# STM32G534xx register map
File version: 1.0
Registers are 32-bit, read-write, reset 0x0 unless marked. A register's access mark holds for its fields unless they carry their own. Offsets are from the block's base; [hi:lo] are bit positions; {n}, {i} and the like mark numbered series; 'fields as' and 'values as' point back to an identical list.

## HRTIM1
Base 0x40010000
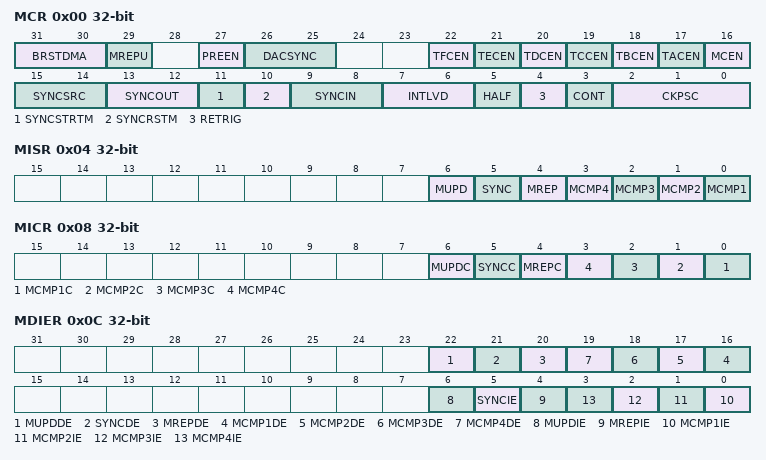
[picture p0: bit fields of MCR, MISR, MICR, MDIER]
0x00 MCR — HRTIM master timer control register
  [31:30] BRSTDMA — Burst DMA update
  [29] MREPU — Master timer repetition update
  [27] PREEN — Preload enable
  [26:25] DACSYNC — DAC synchronization
  [22] TFCEN — Timer F counter enable
  [21] TECEN — Timer E counter enable
  [20] TDCEN — Timer D counter enable
  [19] TCCEN — Timer C counter enable
  [18] TBCEN — Timer B counter enable
  [17] TACEN — Timer A counter enable
  [16] MCEN — Master timer counter enable
  [15:14] SYNCSRC — Synchronization source
  [13:12] SYNCOUT — Synchronization output
  [11] SYNCSTRTM — Synchronization starts master
  [10] SYNCRSTM — Synchronization resets master
  [9:8] SYNCIN — Synchronization input
  [7:6] INTLVD — Interleaved mode
  [5] HALF — Half mode
  [4] RETRIG — Re-triggerable mode
  [3] CONT — Continuous mode
  [2:0] CKPSC — Clock prescaler
0x04 MISR ro — HRTIM master timer interrupt status register
  [6] MUPD — Master update interrupt flag
  [5] SYNC — Sync input interrupt flag
  [4] MREP — Master repetition interrupt flag
  [n-1] MCMP{n} (n=1..4) — Master compare {n} interrupt flag
0x08 MICR — HRTIM master timer interrupt clear register
  [6] MUPDC — Master update interrupt flag clear
  [5] SYNCC — Sync input interrupt flag clear
  [4] MREPC — Repetition interrupt flag clear
  [n-1] MCMP{n}C (n=1..4)
0x0C MDIER — HRTIM master timer DMA interrupt enable register
  [22] MUPDDE — Master update DMA request enable
  [21] SYNCDE — Sync input DMA request enable
  [20] MREPDE
  [n+15] MCMP{n}DE (n=1..4) — Master compare {n} DMA request enable
  [6] MUPDIE — Master update interrupt enable
  [5] SYNCIE — Sync input interrupt enable
  [4] MREPIE — Master repetition interrupt enable
  [n-1] MCMP{n}IE (n=1..4) — Master compare {n} interrupt enable
0x10 MCNTR — HRTIM master timer counter register
  [15:0] MCNT — Counter value
0x14 MPER — HRTIM master timer period register
  [15:0] MPER — Master timer period value
0x18 MREP — HRTIM master timer repetition register
  [7:0] MREP
0x1C MCMP1R — HRTIM master timer compare 1 register
  [15:0] MCMP1 — Master timer compare 1 value
{0x1C+4i} MCMP{i}R (i=2..4) — HRTIM master timer compare {i} register
  [15:0] MCMP{i} — Master timer compare {i} value
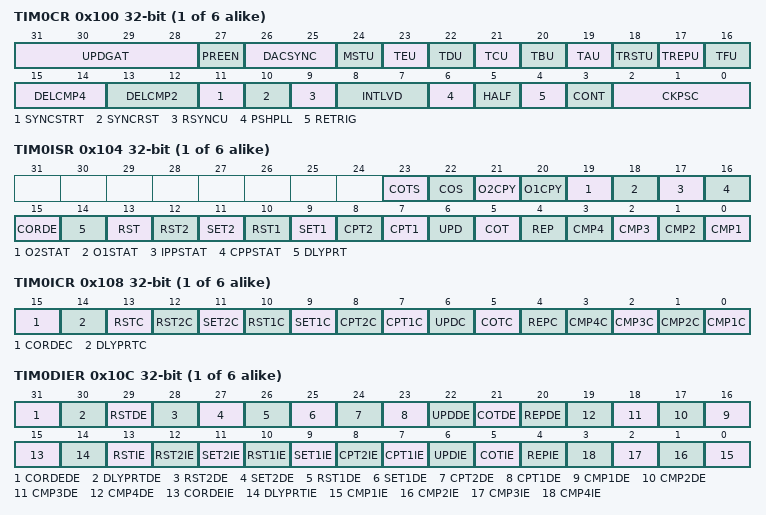
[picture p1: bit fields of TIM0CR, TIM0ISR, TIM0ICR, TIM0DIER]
{0x100+0x100*i} TIM{i}CR (i=0..5) — HRTIM timer x control register
  [31:28] UPDGAT — Update gating
  [27] PREEN — Preload enable
  [26:25] DACSYNC — DAC synchronization
  [24] MSTU — Master timer update
  [23] TEU — Timer E update
  [22] TDU — Timer D update
  [21] TCU — Timer C update
  [20] TBU — Timer B update
  [19] TAU — Timer A update
  [18] TRSTU — Timer x reset update
  [17] TREPU — Timer x repetition update
  [16] TFU — Timer F update
  [15:14] DELCMP4 — CMP4 auto-delayed mode
  [13:12] DELCMP2 — CMP2 auto-delayed mode
  [11] SYNCSTRT — Synchronization starts timer x
  [10] SYNCRST — Synchronization resets timer x
  [9] RSYNCU — Re-synchronized update
  [8:7] INTLVD — Interleaved mode
  [6] PSHPLL — Push-pull mode enable
  [5] HALF — Half mode enable
  [4] RETRIG — Re-triggerable mode
  [3] CONT — Continuous mode
  [2:0] CKPSC — HRTIM timer x clock prescaler
{0x104+0x100*i} TIM{i}ISR ro (i=0..5) — HRTIM timer x interrupt status register
  [23] COTS — Crossbar Override Trigger status
  [22] COS — Crossbar Override status
  [21] O2CPY — Output 2 copy
  [20] O1CPY — Output 1 copy
  [19] O2STAT — Output 2 status
  [18] O1STAT — Output 1 status
  [17] IPPSTAT — Idle push-pull Status
  [16] CPPSTAT — Current push-pull status
  [15] CORDE
  [14] DLYPRT — Delayed protection flag
  [13] RST
  [12] RST2
  [11] SET2
  [10] RST1
  [9] SET1
  [8] CPT2 — Capture 2 interrupt flag
  [7] CPT1 — Capture 1 interrupt flag
  [6] UPD — Update interrupt flag
  [5] COT — Crossbar Override Trigger flag
  [4] REP — Repetition interrupt flag
  [n-1] CMP{n} (n=1..4) — Compare {n} interrupt flag
{0x108+0x100*i} TIM{i}ICR (i=0..5) — HRTIM timer x interrupt clear register
  [15] CORDEC
  [14] DLYPRTC — Delayed protection flag clear
  [13] RSTC — Reset interrupt flag clear
  [12] RST2C — Output 2 reset flag clear timer x
  [11] SET2C — Output 2 set flag clear timer x
  [10] RST1C — Output 1 reset flag clear timer x
  [9] SET1C — Output 1 set flag clear timer x
  [8] CPT2C — Capture 2 interrupt flag clear
  [7] CPT1C — Capture 1 interrupt flag clear
  [6] UPDC — Update interrupt flag clear
  [5] COTC
  [4] REPC — Repetition interrupt flag clear
  [n-1] CMP{n}C (n=1..4) — Compare {n} interrupt flag clear
{0x10C+0x100*i} TIM{i}DIER (i=0..5) — HRTIM timer x DMA interrupt enable register
  [31] CORDEDE
  [30] DLYPRTDE
  [29] RSTDE
  [28] RST2DE
  [27] SET2DE
  [26] RST1DE
  [25] SET1DE
  [24] CPT2DE — Capture 2 DMA request enable
  [23] CPT1DE — Capture 1 DMA request enable
  [22] UPDDE — Update DMA request enable
  [21] COTDE
  [20] REPDE — Repetition DMA request enable
  [n+15] CMP{n}DE (n=1..4) — Compare {n} DMA request enable
  [15] CORDEIE
  [14] DLYPRTIE
  [13] RSTIE — Reset/roll-over interrupt enable
  [12] RST2IE
  [11] SET2IE
  [10] RST1IE
  [9] SET1IE
  [8] CPT2IE — Capture interrupt enable
  [7] CPT1IE — Capture interrupt enable
  [6] UPDIE — Update interrupt enable
  [5] COTIE
  [4] REPIE — Repetition interrupt enable
  [n-1] CMP{n}IE (n=1..4) — Compare {n} interrupt enable
{0x110+0x100*i} CNT{i}R (i=0..5) — HRTIM timer x counter register
  [15:0] CNT — Timer x counter value
{0x114+0x100*i} PER{i}R (i=0..5) — HRTIM timer x period register
  [15:0] PER — Timer x period value
{0x118+0x100*i} REP{i}R (i=0..5) — HRTIM timer x repetition register
  [7:0] REP — Timer x repetition period value
0x11C CMP10R — HRTIM timer x compare 1 register
  [15:0] CMP1 — Timer x compare 1 value
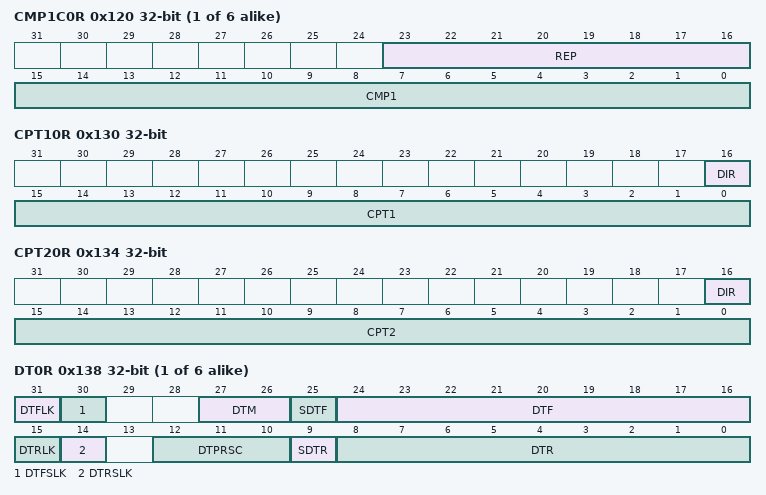
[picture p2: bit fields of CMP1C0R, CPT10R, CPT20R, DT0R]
{0x120+0x100*i} CMP1C{i}R (i=0..5) — HRTIM timer x compare 1 compound register
  [23:16] REP
  [15:0] CMP1 — Timer x compare 1 value
0x124 CMP20R — HRTIM timer x compare 2 register
  [15:0] CMP2 — Timer x compare 2 value
0x128 CMP30R — HRTIM timer x compare 3 register
  [15:0] CMP3 — Timer x compare 3 value
0x12C CMP40R — HRTIM timer x compare 4 register
  [15:0] CMP4 — Timer x compare 4 value
0x130 CPT10R ro — HRTIM timer x capture 1 register
  [16] DIR
  [15:0] CPT1 — Timer x capture 1 value
0x134 CPT20R ro — HRTIM timer x capture 2 register
  [16] DIR
  [15:0] CPT2 — Timer x capture 2 value
{0x138+0x100*i} DT{i}R (i=0..5) — HRTIM timer x deadtime register
  [31] DTFLK — Deadtime falling lock timer x
  [30] DTFSLK
  [27:26] DTM — Deadtime mode
  [25] SDTF
  [24:16] DTF — Deadtime falling value timer x
  [15] DTRLK — Deadtime rising lock timer x
  [14] DTRSLK — Deadtime rising sign lock timer x
  [12:10] DTPRSC — Deadtime prescaler
  [9] SDTR
  [8:0] DTR — Deadtime rising value timer x
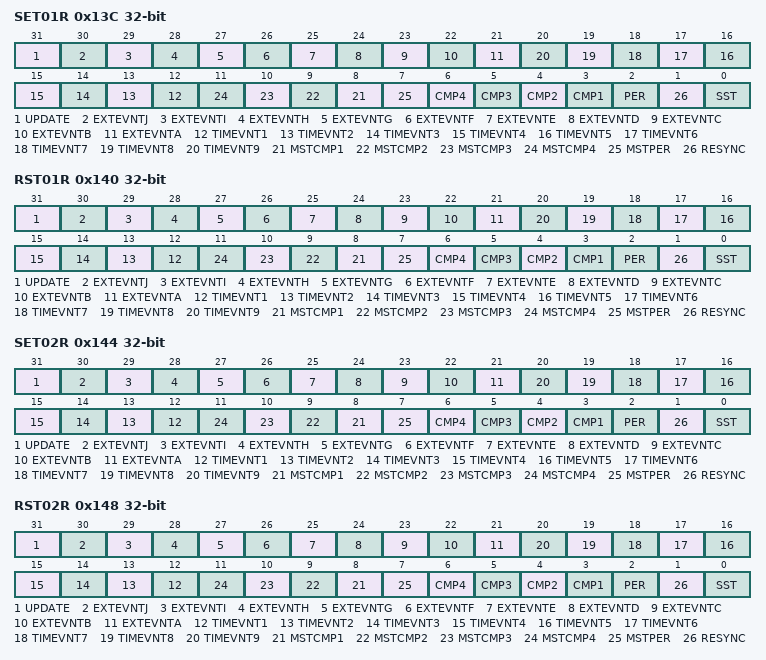
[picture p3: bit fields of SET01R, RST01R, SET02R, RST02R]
0x13C SET01R — HRTIM timer x output 1 set register
  [31] UPDATE
  [30] EXTEVNTJ — External event J
  [29] EXTEVNTI — External event I
  [28] EXTEVNTH — External event H
  [27] EXTEVNTG — External event G
  [26] EXTEVNTF — External event F
  [25] EXTEVNTE — External event E
  [24] EXTEVNTD — External event D
  [23] EXTEVNTC — External event C
  [22] EXTEVNTB — External event B
  [21] EXTEVNTA — External event A
  [n+11] TIMEVNT{n} (n=1..9) — Timer event {n}
  [n+7] MSTCMP{n} (n=1..4) — Master compare {n}
  [7] MSTPER — Master period
  [n+2] CMP{n} (n=1..4) — Timer x compare {n}
  [2] PER — Timer x period
  [1] RESYNC — Timer A resynchronization
  [0] SST — Software set trigger
0x140 RST01R — HRTIM timer x output 1 reset register
  fields as SET01R
0x144 SET02R — HRTIM timer x output 2 set register
  fields as SET01R
0x148 RST02R — HRTIM timer x output 2 reset register
  fields as SET01R
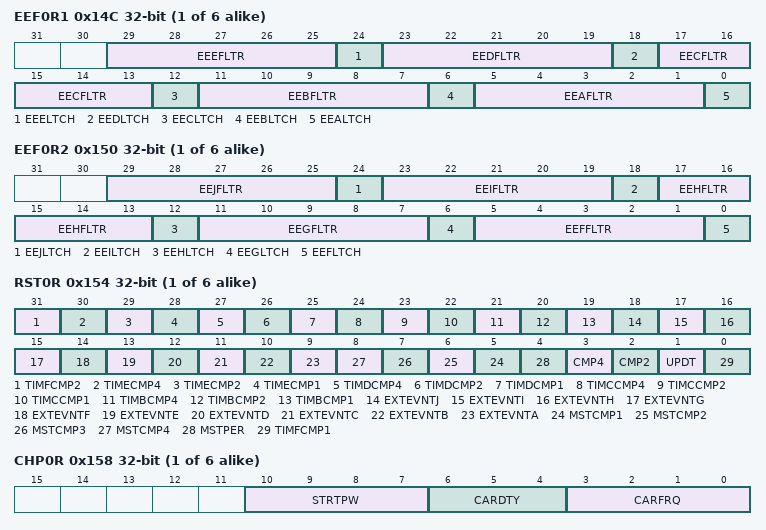
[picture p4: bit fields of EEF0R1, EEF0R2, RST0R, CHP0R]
{0x14C+0x100*i} EEF{i}R1 (i=0..5) — HRTIM timer x external event filtering register 1
  [29:25] EEEFLTR — External event E filter
  [24] EEELTCH — External event E latch
  [23:19] EEDFLTR — External event D filter
  [18] EEDLTCH — External event D latch
  [17:13] EECFLTR — External event C filter
  [12] EECLTCH — External event C latch
  [11:7] EEBFLTR — External event B filter
  [6] EEBLTCH — External event B latch
  [5:1] EEAFLTR — External event A filter
  [0] EEALTCH — External event A latch
{0x150+0x100*i} EEF{i}R2 (i=0..5) — HRTIM timer x external event filtering register 2
  [29:25] EEJFLTR — External event J filter
  [24] EEJLTCH — External event J latch
  [23:19] EEIFLTR — External event I filter
  [18] EEILTCH — External event I latch
  [17:13] EEHFLTR — External event H filter
  [12] EEHLTCH — External event H latch
  [11:7] EEGFLTR — External event G filter
  [6] EEGLTCH — External event G latch
  [5:1] EEFFLTR — External event F filter
  [0] EEFLTCH — External event F latch
{0x154+0x100*i} RST{i}R (i=0..5) — HRTIM timer x reset register
  [31] TIMFCMP2 — Timer F compare 2
  [30] TIMECMP4 — Timer E compare 4
  [29] TIMECMP2 — Timer E compare 2
  [28] TIMECMP1 — Timer E compare 1
  [27] TIMDCMP4 — Timer D compare 4
  [26] TIMDCMP2 — Timer D compare 2
  [25] TIMDCMP1 — Timer D compare 1
  [24] TIMCCMP4 — Timer C compare 4
  [23] TIMCCMP2 — Timer C compare 2
  [22] TIMCCMP1 — Timer C compare 1
  [21] TIMBCMP4 — Timer B compare 4
  [20] TIMBCMP2 — Timer B compare 2
  [19] TIMBCMP1 — Timer B compare 1
  [18] EXTEVNTJ — External event J
  [17] EXTEVNTI — External event I
  [16] EXTEVNTH — External event H
  [15] EXTEVNTG — External event G
  [14] EXTEVNTF — External event F
  [13] EXTEVNTE — External event E
  [12] EXTEVNTD — External event D
  [11] EXTEVNTC — External event C
  [10] EXTEVNTB — External event B
  [9] EXTEVNTA — External event A
  [n+4] MSTCMP{n} (n=1..4) — Master compare {n}
  [4] MSTPER — Master timer period
  [3] CMP4 — Timer A compare 4 reset
  [2] CMP2 — Timer A compare 2 reset
  [1] UPDT — Timer A update reset
  [0] TIMFCMP1 — Timer F compare 1
{0x158+0x100*i} CHP{i}R (i=0..5) — HRTIM timer x chopper register
  [10:7] STRTPW — Timer x start pulsewidth
  [6:4] CARDTY — Timer x chopper duty cycle value
  [3:0] CARFRQ — Timer x carrier frequency value
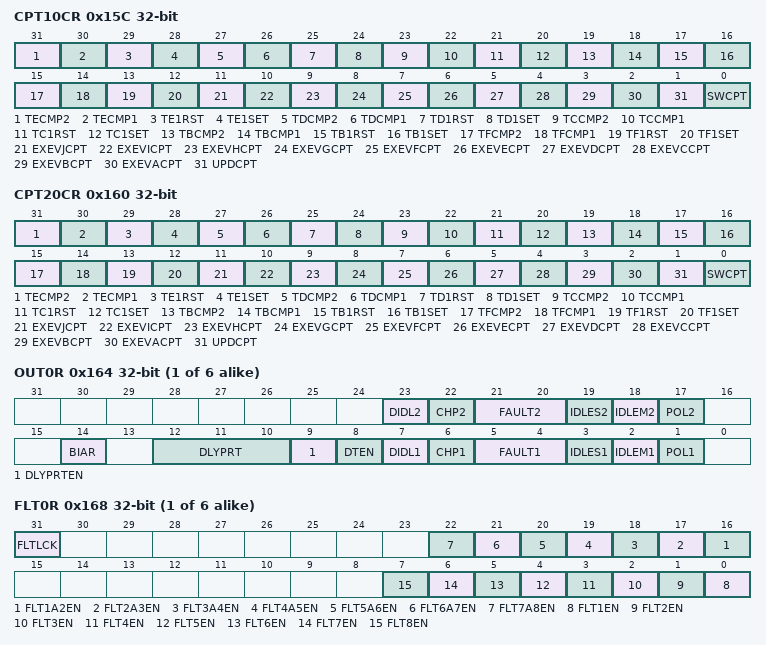
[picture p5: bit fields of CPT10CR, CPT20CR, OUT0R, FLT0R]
0x15C CPT10CR — HRTIM timer x capture 1 control register
  [31] TECMP2 — Timer E compare 2
  [30] TECMP1 — Timer E compare 1
  [29] TE1RST — Timer E output 1 reset
  [28] TE1SET — Timer E output 1 set
  [27] TDCMP2 — Timer D compare 2
  [26] TDCMP1 — Timer D compare 1
  [25] TD1RST — Timer D output 1 reset
  [24] TD1SET — Timer D output 1 set
  [23] TCCMP2 — Timer C compare 2
  [22] TCCMP1 — Timer C compare 1
  [21] TC1RST — Timer C output 1 reset
  [20] TC1SET — Timer C output 1 set
  [19] TBCMP2 — Timer B compare 2
  [18] TBCMP1 — Timer B compare 1
  [17] TB1RST — Timer B output 1 reset
  [16] TB1SET — Timer B output 1 set
  [15] TFCMP2 — Timer E compare 2
  [14] TFCMP1 — Timer F compare 1
  [13] TF1RST — Timer F output 1 reset
  [12] TF1SET — Timer F output 1 set
  [11] EXEVJCPT — External event J capture
  [10] EXEVICPT — External event I capture
  [9] EXEVHCPT — External event H capture
  [8] EXEVGCPT — External event G capture
  [7] EXEVFCPT — External event F capture
  [6] EXEVECPT — External event E capture
  [5] EXEVDCPT — External event D capture
  [4] EXEVCCPT — External event C capture
  [3] EXEVBCPT — External event B capture
  [2] EXEVACPT — External event A capture
  [1] UPDCPT — Update capture
  [0] SWCPT — Software capture
0x160 CPT20CR — HRTIM timer x capture 2 control register
  fields as CPT10CR
{0x164+0x100*i} OUT{i}R (i=0..5) — HRTIM timer x output register
  [23] DIDL2
  [22] CHP2 — Output 2 chopper enable
  [21:20] FAULT2 — Output 2 fault state
  [19] IDLES2 — Output 2 idle state
  [18] IDLEM2 — Output 2 idle mode
  [17] POL2 — Output 2 polarity
  [14] BIAR — Balanced Idle Automatic Resume
  [12:10] DLYPRT — Delayed protection
  [9] DLYPRTEN — Delayed protection enable
  [8] DTEN — Deadtime enable
  [7] DIDL1
  [6] CHP1 — Output 1 chopper enable
  [5:4] FAULT1 — Output 1 fault state
  [3] IDLES1 — Output 1 Idle State
  [2] IDLEM1 — Output 1 Idle mode
  [1] POL1 — Output 1 polarity
{0x168+0x100*i} FLT{i}R (i=0..5) — HRTIM timer x fault register
  [31] FLTLCK — Fault sources lock
  [n+15] FLT{n}A{n+1}EN (n=1..7) — Fault {n} AND Fault {n+1} enable
  [n-1] FLT{n}EN (n=1..8) — Fault {n} enable
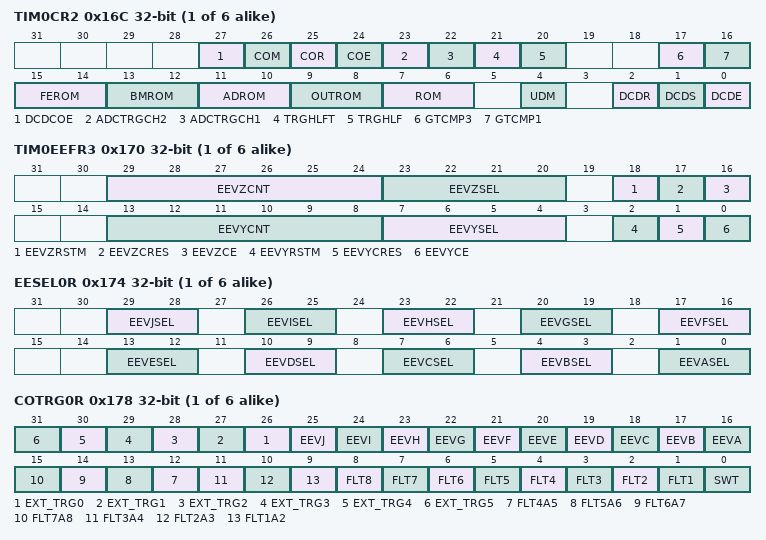
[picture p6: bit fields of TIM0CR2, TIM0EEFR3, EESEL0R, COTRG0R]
{0x16C+0x100*i} TIM{i}CR2 (i=0..5) — HRTIM timer x control register 2
  [27] DCDCOE
  [26] COM — Crossbar override mode
  [25] COR — Crossbar override rearm
  [24] COE — Crossbar override enable
  [23] ADCTRGCH2 — ADC trigger for channel 2
  [22] ADCTRGCH1 — ADC trigger for channel 1
  [21] TRGHLFT — Triggered-half timeout mode
  [20] TRGHLF — Triggered-half mode
  [17] GTCMP3 — Greater than compare 3 PWM mode
  [16] GTCMP1 — Greater than compare 1 PWM mode
  [15:14] FEROM — Fault and event roll-over mode
  [13:12] BMROM — Burst mode roll-over mode
  [11:10] ADROM — ADC roll-over mode
  [9:8] OUTROM — Output roll-over mode
  [7:6] ROM — Roll-over mode
  [4] UDM — Up-Down mode
  [2] DCDR — Dual channel DAC reset trigger
  [1] DCDS — Dual channel DAC Step trigger
  [0] DCDE — Dual channel DAC trigger enable
{0x170+0x100*i} TIM{i}EEFR3 (i=0..5) — HRTIM timer x external event filtering register 3
  [29:24] EEVZCNT — External Event Z Counter
  [23:20] EEVZSEL — External Event Z Selection
  [18] EEVZRSTM
  [17] EEVZCRES — External Event Z Counter Reset
  [16] EEVZCE — External Event Z Counter Enable
  [13:8] EEVYCNT — External Event Y Selection
  [7:4] EEVYSEL — External Event Y Selection
  [2] EEVYRSTM
  [1] EEVYCRES — External Event Y Counter Reset
  [0] EEVYCE — External Event Y Counter Enable
{0x174+0x100*i} EESEL{i}R (i=0..5) — HRTIM timer x external event selection register
  [29:28] EEVJSEL — External event J selection
  [26:25] EEVISEL — External event I selection
  [23:22] EEVHSEL — External event H selection
  [20:19] EEVGSEL — External event G selection
  [17:16] EEVFSEL — External event F selection
  [13:12] EEVESEL — External event E selection
  [10:9] EEVDSEL — External event D selection
  [7:6] EEVCSEL — External event C selection
  [4:3] EEVBSEL — External event B selection
  [1:0] EEVASEL — External event A selection
{0x178+0x100*i} COTRG{i}R (i=0..5) — HRTIM timer x crossbar override trigger register
  [n+26] EXT_TRG{n} (n=0..5) — External trigger {n}
  [25] EEVJ — EEVJ trigger
  [24] EEVI — EEVI trigger
  [23] EEVH — EEVH trigger
  [22] EEVG — EEVG trigger
  [21] EEVF — EEVF trigger
  [20] EEVE — EEVE trigger
  [19] EEVD — EEVD trigger
  [18] EEVC — EEVC trigger
  [17] EEVB — EEVB trigger
  [16] EEVA — EEVA trigger
  [n+8] FLT{n}A{n+1} (n=4..7) — FLT{n}A{n+1} trigger
  [11] FLT3A4 — FLT2A3 trigger
  [10] FLT2A3 — FLT2A3 trigger
  [9] FLT1A2 — FLT1A2 trigger
  [n] FLT{n} (n=1..8) — FLT{n} trigger
  [0] SWT — Software trigger
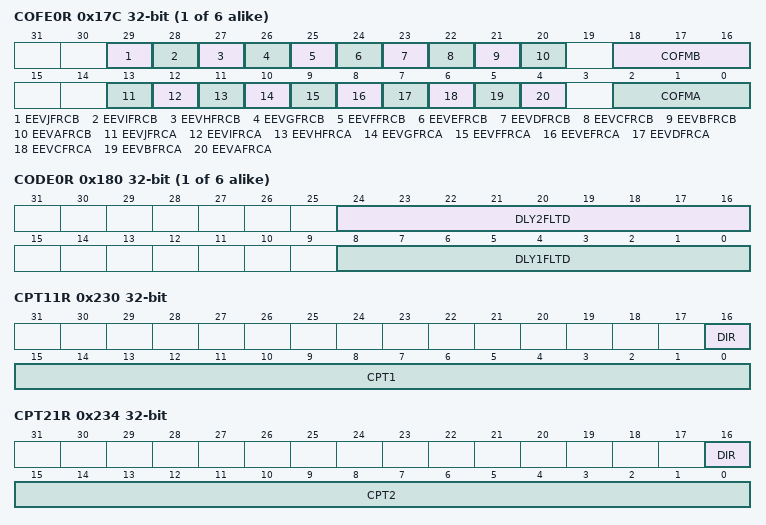
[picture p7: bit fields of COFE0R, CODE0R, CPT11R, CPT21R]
{0x17C+0x100*i} COFE{i}R (i=0..5) — HRTIM timer x crossbar override forcing event register
  [29] EEVJFRCB — External event J forces output B
  [28] EEVIFRCB — External event I forces output B
  [27] EEVHFRCB — External event H forces output B
  [26] EEVGFRCB — External event G forces output B
  [25] EEVFFRCB — External event F forces output B
  [24] EEVEFRCB — External event E forces output B
  [23] EEVDFRCB — External event D forces output B
  [22] EEVCFRCB — External event C forces output B
  [21] EEVBFRCB — External event B forces output B
  [20] EEVAFRCB — External event A forces output B
  [18:16] COFMB
  [13] EEVJFRCA — External event J forces output A
  [12] EEVIFRCA — External event I forces output A
  [11] EEVHFRCA — External event H forces output A
  [10] EEVGFRCA — External event G forces output A
  [9] EEVFFRCA — External event F forces output A
  [8] EEVEFRCA — External event E forces output A
  [7] EEVDFRCA — External event D forces output A
  [6] EEVCFRCA — External event C forces output A
  [5] EEVBFRCA — External event B forces output A
  [4] EEVAFRCA — External event A forces output A
  [2:0] COFMA
{0x180+0x100*i} CODE{i}R (i=0..5) — HRTIM timer x crossbar override delayed fault event register
  [24:16] DLY2FLTD — Delayed 2 Fault duration
  [8:0] DLY1FLTD — Delayed 1 Fault duration
0x21C CMP11R — HRTIM timer x compare 1 register
  [15:0] CMP1 — Timer x compare 1 value
0x224 CMP21R — HRTIM timer x compare 2 register
  [15:0] CMP2 — Timer x compare 2 value
0x228 CMP31R — HRTIM timer x compare 3 register
  [15:0] CMP3 — Timer x compare 3 value
0x22C CMP41R — HRTIM timer x compare 4 register
  [15:0] CMP4 — Timer x compare 4 value
0x230 CPT11R ro — HRTIM timer x capture 1 register
  [16] DIR
  [15:0] CPT1 — Timer x capture 1 value
0x234 CPT21R ro — HRTIM timer x capture 2 register
  [16] DIR
  [15:0] CPT2 — Timer x capture 2 value
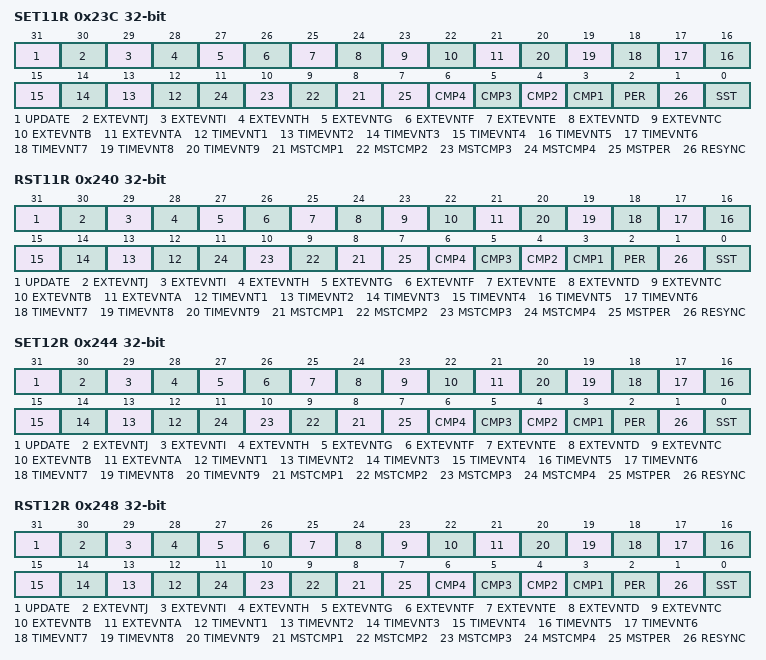
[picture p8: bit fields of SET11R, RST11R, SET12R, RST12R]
0x23C SET11R — HRTIM timer x output 1 set register
  fields as SET01R
0x240 RST11R — HRTIM timer x output 1 reset register
  fields as SET01R
0x244 SET12R — HRTIM timer x output 2 set register
  fields as SET01R
0x248 RST12R — HRTIM timer x output 2 reset register
  fields as SET01R
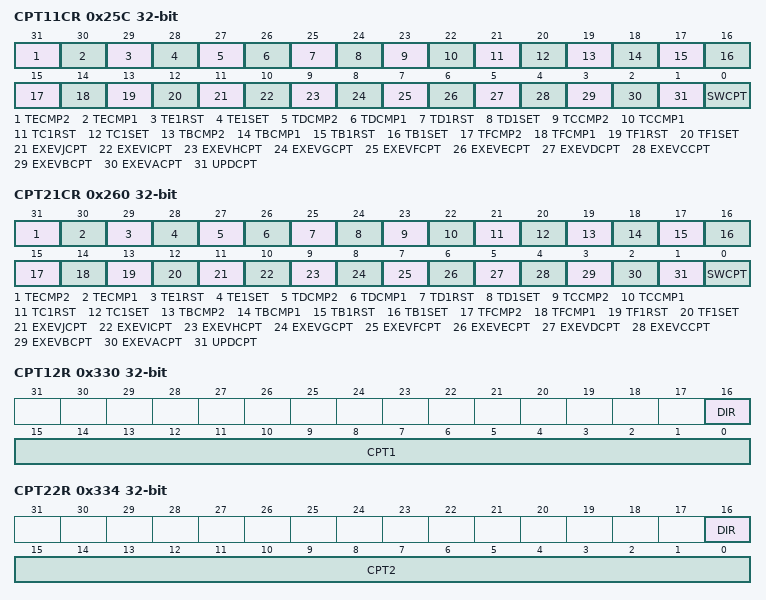
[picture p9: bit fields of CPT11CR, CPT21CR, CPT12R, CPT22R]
0x25C CPT11CR — HRTIM timer x capture 1 control register
  fields as CPT10CR
0x260 CPT21CR — HRTIM timer x capture 2 control register
  fields as CPT10CR
0x31C CMP12R — HRTIM timer x compare 1 register
  [15:0] CMP1 — Timer x compare 1 value
0x324 CMP22R — HRTIM timer x compare 2 register
  [15:0] CMP2 — Timer x compare 2 value
0x328 CMP32R — HRTIM timer x compare 3 register
  [15:0] CMP3 — Timer x compare 3 value
0x32C CMP42R — HRTIM timer x compare 4 register
  [15:0] CMP4 — Timer x compare 4 value
0x330 CPT12R ro — HRTIM timer x capture 1 register
  [16] DIR
  [15:0] CPT1 — Timer x capture 1 value
0x334 CPT22R ro — HRTIM timer x capture 2 register
  [16] DIR
  [15:0] CPT2 — Timer x capture 2 value
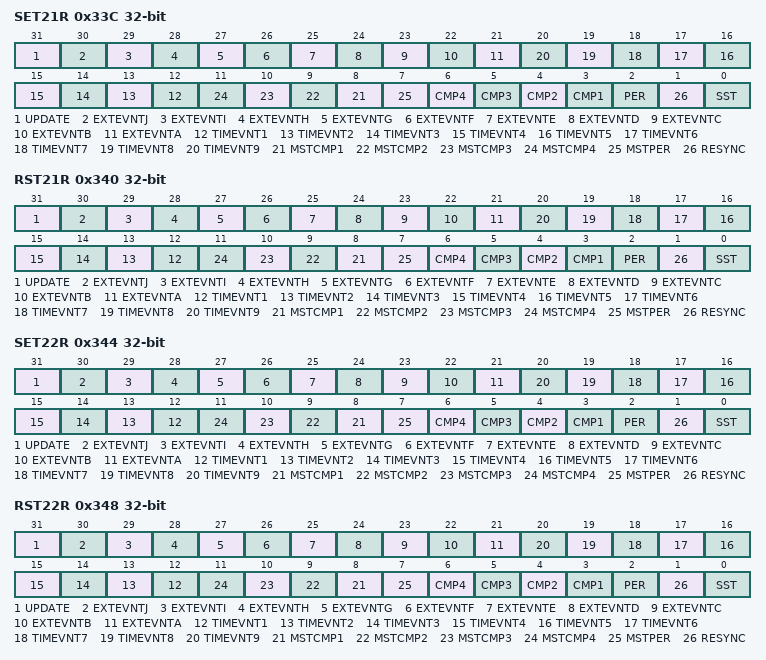
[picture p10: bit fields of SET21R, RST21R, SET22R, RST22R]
0x33C SET21R — HRTIM timer x output 1 set register
  fields as SET01R
0x340 RST21R — HRTIM timer x output 1 reset register
  fields as SET01R
0x344 SET22R — HRTIM timer x output 2 set register
  fields as SET01R
0x348 RST22R — HRTIM timer x output 2 reset register
  fields as SET01R
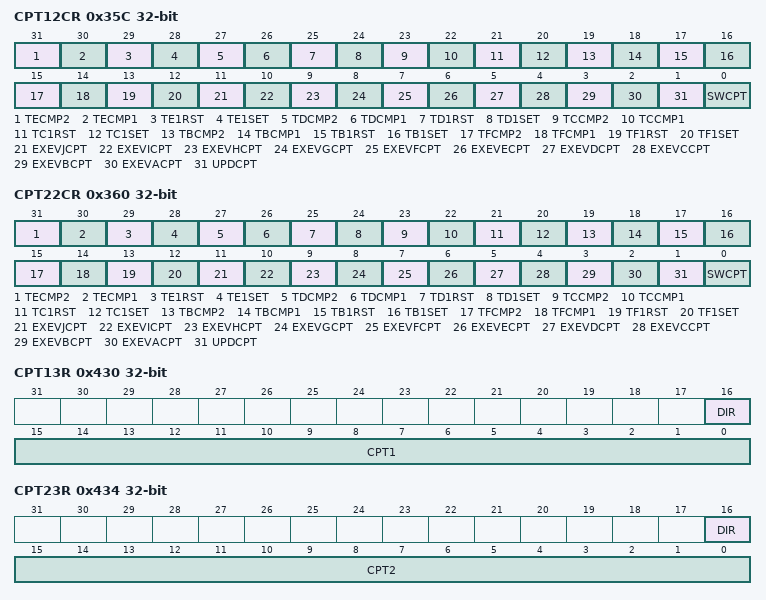
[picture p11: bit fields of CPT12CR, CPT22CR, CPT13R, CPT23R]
0x35C CPT12CR — HRTIM timer x capture 1 control register
  fields as CPT10CR
0x360 CPT22CR — HRTIM timer x capture 2 control register
  fields as CPT10CR
0x41C CMP13R — HRTIM timer x compare 1 register
  [15:0] CMP1 — Timer x compare 1 value
0x424 CMP23R — HRTIM timer x compare 2 register
  [15:0] CMP2 — Timer x compare 2 value
0x428 CMP33R — HRTIM timer x compare 3 register
  [15:0] CMP3 — Timer x compare 3 value
0x42C CMP43R — HRTIM timer x compare 4 register
  [15:0] CMP4 — Timer x compare 4 value
0x430 CPT13R ro — HRTIM timer x capture 1 register
  [16] DIR
  [15:0] CPT1 — Timer x capture 1 value
0x434 CPT23R ro — HRTIM timer x capture 2 register
  [16] DIR
  [15:0] CPT2 — Timer x capture 2 value
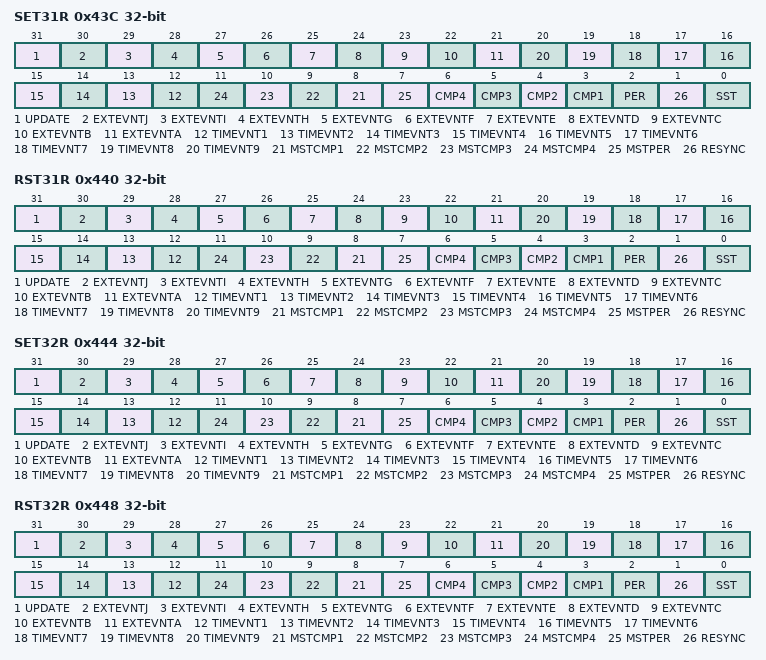
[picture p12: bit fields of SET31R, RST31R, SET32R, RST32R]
0x43C SET31R — HRTIM timer x output 1 set register
  fields as SET01R
0x440 RST31R — HRTIM timer x output 1 reset register
  fields as SET01R
0x444 SET32R — HRTIM timer x output 2 set register
  fields as SET01R
0x448 RST32R — HRTIM timer x output 2 reset register
  fields as SET01R
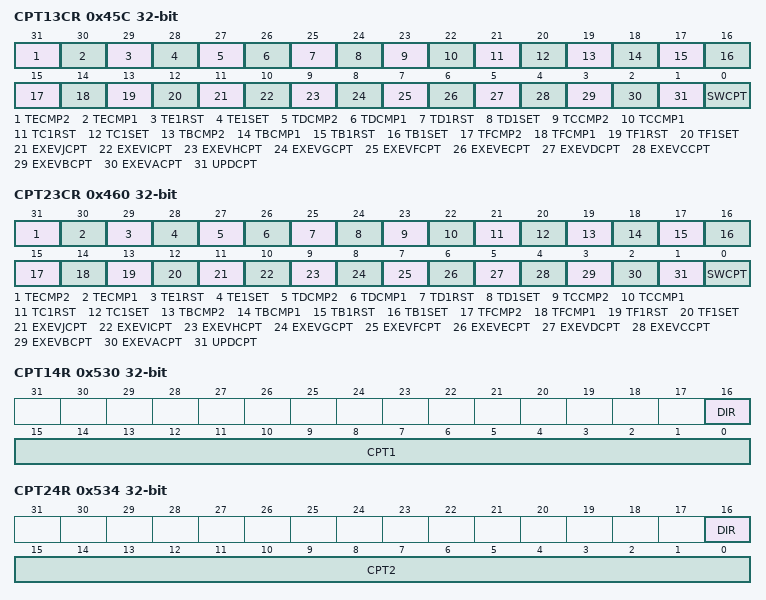
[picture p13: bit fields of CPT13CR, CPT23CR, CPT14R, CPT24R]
0x45C CPT13CR — HRTIM timer x capture 1 control register
  fields as CPT10CR
0x460 CPT23CR — HRTIM timer x capture 2 control register
  fields as CPT10CR
0x51C CMP14R — HRTIM timer x compare 1 register
  [15:0] CMP1 — Timer x compare 1 value
0x524 CMP24R — HRTIM timer x compare 2 register
  [15:0] CMP2 — Timer x compare 2 value
0x528 CMP34R — HRTIM timer x compare 3 register
  [15:0] CMP3 — Timer x compare 3 value
0x52C CMP44R — HRTIM timer x compare 4 register
  [15:0] CMP4 — Timer x compare 4 value
0x530 CPT14R ro — HRTIM timer x capture 1 register
  [16] DIR
  [15:0] CPT1 — Timer x capture 1 value
0x534 CPT24R ro — HRTIM timer x capture 2 register
  [16] DIR
  [15:0] CPT2 — Timer x capture 2 value
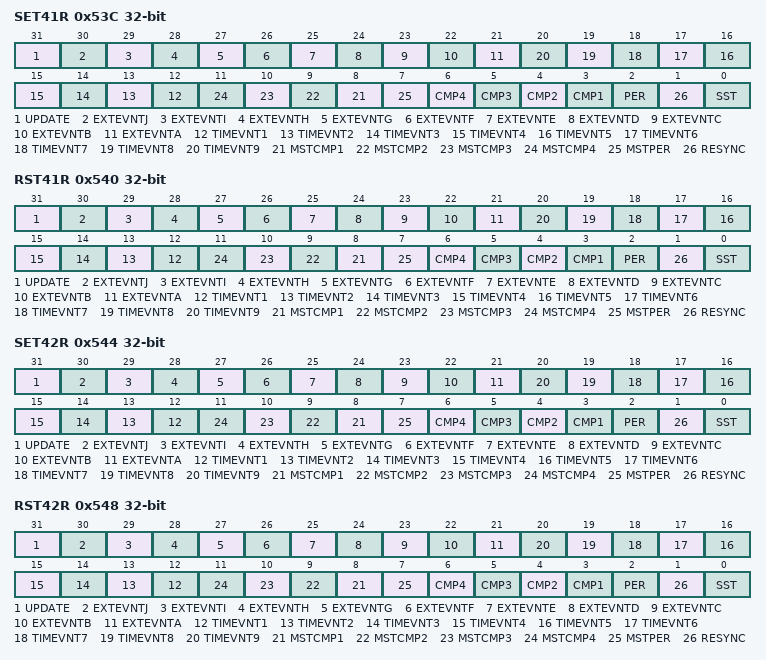
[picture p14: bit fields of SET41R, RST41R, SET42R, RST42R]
0x53C SET41R — HRTIM timer x output 1 set register
  fields as SET01R
0x540 RST41R — HRTIM timer x output 1 reset register
  fields as SET01R
0x544 SET42R — HRTIM timer x output 2 set register
  fields as SET01R
0x548 RST42R — HRTIM timer x output 2 reset register
  fields as SET01R
0x55C CPT14CR — HRTIM timer x capture 1 control register
  fields as CPT10CR
0x560 CPT24CR — HRTIM timer x capture 2 control register
  fields as CPT10CR
0x61C CMP15R — HRTIM timer x compare 1 register
  [15:0] CMP1 — Timer x compare 1 value
0x624 CMP25R — HRTIM timer x compare 2 register
  [15:0] CMP2 — Timer x compare 2 value
0x628 CMP35R — HRTIM timer x compare 3 register
  [15:0] CMP3 — Timer x compare 3 value
0x62C CMP45R — HRTIM timer x compare 4 register
  [15:0] CMP4 — Timer x compare 4 value
0x630 CPT15R ro — HRTIM timer x capture 1 register
  [16] DIR
  [15:0] CPT1 — Timer x capture 1 value
0x634 CPT25R ro — HRTIM timer x capture 2 register
  [16] DIR
  [15:0] CPT2 — Timer x capture 2 value
0x63C SET51R — HRTIM timer x output 1 set register
  fields as SET01R
0x640 RST51R — HRTIM timer x output 1 reset register
  fields as SET01R
0x644 SET52R — HRTIM timer x output 2 set register
  fields as SET01R
0x648 RST52R — HRTIM timer x output 2 reset register
  fields as SET01R
0x65C CPT15CR — HRTIM timer x capture 1 control register
  fields as CPT10CR
0x660 CPT25CR — HRTIM timer x capture 2 control register
  fields as CPT10CR
0x700 CR1 — HRTIM control register 1
  [3n+15:3n+13] AD{n}USRC (n=1..4) — ADC trigger {n} update source
  [14] RTFUDIS — Remote Timer F update disable
  [13] RTEUDIS — Remote Timer E update disable
  [12] RTDUDIS — Remote Timer D update disable
  [11] RTCUDIS — Remote Timer C update disable
  [10] RTBUDIS — Remote Timer B update disable
  [9] RTAUDIS — Remote timer A update disable
  [8] RMUDIS — Remote master update disable
  [6] TFUDIS — Timer F update disable
  [5] TEUDIS — Timer E update disable
  [4] TDUDIS — Timer D update disable
  [3] TCUDIS — Timer C update disable
  [2] TBUDIS — Timer B update disable
  [1] TAUDIS — Timer A update disable
  [0] MUDIS — Master update disable
0x704 CR2 — HRTIM control register 2
  [26:24] DBSS — DMA burst source selection
  [21] SWPF — Swap timer F outputs
  [20] SWPE — Swap timer E outputs
  [19] SWPD — Swap timer D outputs
  [18] SWPC — Swap timer C outputs
  [17] SWPB — Swap timer B outputs
  [16] SWPA — Swap timer A outputs
  [14] TFRST — Timer F counter software reset
  [13] TERST — Timer E counter software reset
  [12] TDRST — Timer D counter software reset
  [11] TCRST — Timer C counter software reset
  [10] TBRST — Timer B counter software reset
  [9] TARST — Timer A counter software reset
  [8] MRST — Master counter software reset
  [6] TFSWU — Timer F software update
  [5] TESWU — Timer E software update
  [4] TDSWU — Timer D software update
  [3] TCSWU — Timer C software update
  [2] TBSWU — Timer B software update
  [1] TASWU — Timer A software update
  [0] MSWU — Master timer software update
0x708 ISR ro — HRTIM interrupt status register
  [17] BMPER — Burst mode period interrupt flag
  [16] DLLRDY — DLL Ready Interrupt Flag
  [8] FLT8 — Fault 8 interrupt flag
  [7] FLT7 — Fault 7 interrupt flag
  [6] FLT6 — Fault 6 interrupt flag
  [5] SYSFLT — System fault interrupt flag
  [n-1] FLT{n} (n=1..5) — Fault {n} interrupt flag
0x70C ICR — HRTIM interrupt clear register
  [17] BMPERC — Burst mode period flag clear
  [16] DLLRDYC — DLL Ready Interrupt flag Clear
  [8] FLT8C — Fault 8 interrupt flag clear
  [7] FLT7C — Fault 7 interrupt flag clear
  [6] FLT6C — Fault 6 interrupt flag clear
  [5] SYSFLTC — System fault interrupt flag clear
  [n-1] FLT{n}C (n=1..5) — Fault {n} interrupt flag clear
0x710 IER — HRTIM interrupt enable register
  [17] BMPERIE — Burst mode period interrupt enable
  [16] DLLRDYIE — DLL Ready Interrupt Enable
  [8] FLT8IE — Fault 8 interrupt enable
  [7] FLT7IE — Fault 7 interrupt enable
  [6] FLT6IE — Fault 6 interrupt enable
  [5] SYSFLTIE — System fault interrupt enable
  [n-1] FLT{n}IE (n=1..5) — Fault {n} interrupt enable
0x714 OENR — HRTIM output enable register
  [11] TF2OEN — Timer F output 2 enable
  [10] TF1OEN — Timer F output 1 enable
  [9] TE2OEN — Timer E output 2 enable
  [8] TE1OEN — Timer E output 1 enable
  [7] TD2OEN — Timer D output 2 enable
  [6] TD1OEN — Timer D output 1 enable
  [5] TC2OEN — Timer C output 2 enable
  [4] TC1OEN — Timer C output 1 enable
  [3] TB2OEN — Timer B output 2 enable
  [2] TB1OEN — Timer B output 1 enable
  [1] TA2OEN — Timer A output 2 enable
  [0] TA1OEN — Timer A output 1 enable
0x718 ODISR — HRTIM output disable register
  [11] TF2ODIS — Timer F output 2 disable
  [10] TF1ODIS — Timer F output 1 disable
  [9] TE2ODIS — Timer E output 2 disable
  [8] TE1ODIS — Timer E output 1 disable
  [7] TD2ODIS — Timer D output 2 disable
  [6] TD1ODIS — Timer D output 1 disable
  [5] TC2ODIS — Timer C output 2 disable
  [4] TC1ODIS — Timer C output 1 disable
  [3] TB2ODIS — Timer B output 2 disable
  [2] TB1ODIS — Timer B output 1 disable
  [1] TA2ODIS — Timer A output 2 disable
  [0] TA1ODIS — Timer A output 1 disable
0x71C ODSR ro — HRTIM output disable status register
  [11] TF2ODS — Timer F output 2 disable status
  [10] TF1ODS — Timer F output 1 disable status
  [9] TE2ODS — Timer E output 2 disable status
  [8] TE1ODS — Timer E output 1 disable status
  [7] TD2ODS — Timer D output 2 disable status
  [6] TD1ODS — Timer D output 1 disable status
  [5] TC2ODS — Timer C output 2 disable status
  [4] TC1ODS — Timer C output 1 disable status
  [3] TB2ODS — Timer B output 2 disable status
  [2] TB1ODS — Timer B output 1 disable status
  [1] TA2ODS — Timer A output 2 disable status
  [0] TA1ODS — Timer A output 1 disable status
0x720 BMCR — HRTIM burst mode control register
  [31] BMSTAT — Burst mode status
  [22] TFBM — Timer F burst mode
  [21] TEBM — Timer E burst mode
  [20] TDBM — Timer D burst mode
  [19] TCBM — Timer C burst mode
  [18] TBBM — Timer B burst mode
  [17] TABM — Timer A burst mode
  [16] MTBM — Master timer burst mode
  [10] BMPREN — Burst mode preload enable
  [9:6] BMPRSC — Burst mode prescaler
  [5:2] BMCLK — Burst mode clock source
  [1] BMOM — Burst mode operating mode
  [0] BME — Burst mode enable
0x724 BMTRGR — HRTIM burst mode trigger register
  [31] OCHPEV — On-chip event
  [30] EEVH
  [29] EEVG
  [28] TDEEVH
  [27] TAEEVG
  [26] TECMP2 — Timer E compare 2 event
  [25] TECMP1 — Timer E compare 1 event
  [24] TEREP — Timer E repetition
  [23] TFCMP1 — Timer F compare 1 event
  [22] TDCMP2 — Timer D compare 2 event
  [21] TFREP — Timer F repetition
  [20] TDREP — Timer D repetition
  [19] TDRST — Timer D reset or roll-over
  [18] TFRST — Timer F reset
  [17] TCCMP1 — Timer C compare 1 event
  [16] TCREP — Timer C repetition
  [15] TCRST — Timer C reset or roll-over
  [14] TBCMP2 — Timer B compare 2 event
  [13] TBCMP1 — Timer B compare 1 event
  [12] TBREP — Timer B repetition
  [11] TBRST — Timer B reset or roll-over
  [10] TACMP2 — Timer A compare 2 event
  [9] TACMP1 — Timer A compare 1 event
  [8] TAREP — Timer A repetition
  [7] TARST — Timer A reset or roll-over
  [n+2] MSTCMP{n} (n=1..4) — Master compare {n}
  [2] MSTREP — Master repetition
  [1] MSTRST — Master reset or roll-over
  [0] SW — Software start
0x728 BMCMPR — HRTIM burst mode compare register
  [15:0] BMCMP — Burst mode compare value
0x72C BMPER — HRTIM burst mode period register
  [15:0] BMPER — Burst mode period
0x730 EECR1 — HRTIM timer external event control register 1
  [6n-1] EE{n}FAST (n=1..5) — External event {n} fast mode
  [6n-2:6n-3] EE{n}SNS (n=1..5) — External event {n} sensitivity
  [6n-4] EE{n}POL (n=1..5) — External event {n} polarity
  [6n-5:6n-6] EE{n}SRC (n=1..5) — External event {n} source
0x734 EECR2 — HRTIM timer external event control register 2
  [6n-32:6n-33] EE{n}SNS (n=6..10) — External event {n} sensitivity
  [6n-34] EE{n}POL (n=6..10) — External event {n} polarity
  [6n-35:6n-36] EE{n}SRC (n=6..10) — External event {n} source
0x738 EECR3 — HRTIM timer external event control register 3
  [31:30] EEVSD
  [6n-33:6n-36] EE{n}F (n=6..10) — External event {n} filter
0x73C ADC1R — HRTIM ADC trigger 1 register
  [31] ADC1TEPER — ADC trigger 1 on timer E period
  [30] ADC1TEC4 — ADC trigger 1 on timer E compare 4
  [29] ADC1TEC3 — ADC trigger 1 on timer E compare 3
  [28] ADC1TFRST
  [27] ADC1TDPER — ADC trigger 1 on timer D period
  [26] ADC1TDC4 — ADC trigger 1 on timer D compare 4
  [25] ADC1TDC3 — ADC trigger 1 on timer D compare 3
  [24] ADC1TFPER — ADC trigger 1 on timer F period
  [23] ADC1TCPER — ADC trigger 1 on timer C period
  [22] ADC1TCC4 — ADC trigger 1 on timer C compare 4
  [21] ADC1TCC3 — ADC trigger 1 on timer C compare 3
  [20] ADC1TFC4 — ADC trigger 1 on timer F compare 4
  [19] ADC1TBRST
  [18] ADC1TBPER — ADC trigger 1 on timer B period
  [17] ADC1TBC4 — ADC trigger 1 on timer B compare 4
  [16] ADC1TBC3 — ADC trigger 1 on timer B compare 3
  [15] ADC1TFC3 — ADC trigger 1 on timer F compare 3
  [14] ADC1TARST
  [13] ADC1TAPER — ADC trigger 1 on timer A period
  [12] ADC1TAC4 — ADC trigger 1 on timer A compare 4
  [11] ADC1TAC3 — ADC trigger 1 on timer A compare 3
  [10] ADC1TFC2 — ADC trigger 1 on timer F compare 2
  [n+4] ADC1EEV{n} (n=1..5)
  [4] ADC1MPER — ADC trigger 1 on master period
  [n-1] ADC1MC{n} (n=1..4) — ADC trigger 1 on master compare {n}
0x740 ADC2R — HRTIM ADC trigger 2 register
  [31] ADC2TERST
  [30] ADC2TEC4 — ADC trigger 2 on timer E compare 4
  [29] ADC2TEC3 — ADC trigger 2 on timer E compare 3
  [28] ADC2TEC2 — ADC trigger 2 on timer E compare 2
  [27] ADC2TDRST
  [26] ADC2TDPER — ADC trigger 2 on timer D period
  [25] ADC2TDC4 — ADC trigger 2 on timer D compare 4
  [24] ADC2TFPER — ADC trigger 2 on timer F period
  [23] ADC2TDC2 — ADC trigger 2 on timer D compare 2
  [22] ADC2TCRST
  [21] ADC2TCPER — ADC trigger 2 on timer C period
  [20] ADC2TCC4 — ADC trigger 2 on timer C compare 4
  [19] ADC2TFC4 — ADC trigger 2 on timer F compare 4
  [18] ADC2TCC2 — ADC trigger 2 on timer C compare 2
  [17] ADC2TBPER — ADC trigger 2 on timer B period
  [16] ADC2TBC4 — ADC trigger 2 on timer B compare 4
  [15] ADC2TFC3 — ADC trigger 2 on timer F compare 3
  [14] ADC2TBC2 — ADC trigger 2 on timer B compare 2
  [13] ADC2TAPER — ADC trigger 2 on timer A period
  [12] ADC2TAC4 — ADC trigger 2 on timer A compare 4
  [11] ADC2TFC2 — ADC trigger 2 on timer F compare 2
  [10] ADC2TAC2 — ADC trigger 2 on timer A compare 2
  [n-1] ADC2EEV{n} (n=6..10)
  [4] ADC2MPER — ADC trigger 2 on master period
  [n-1] ADC2MC{n} (n=1..4) — ADC trigger 2 on master compare {n}
0x744 ADC3R — HRTIM ADC trigger 3 register
  [31] ADC3TEPER — ADC trigger 3 on timer E period
  [30] ADC3TEC4 — ADC trigger 3 on timer E compare 4
  [29] ADC3TEC3 — ADC trigger 3 on timer E compare 3
  [28] ADC3TFRST
  [27] ADC3TDPER — ADC trigger 3 on timer D period
  [26] ADC3TDC4 — ADC trigger 3 on timer D compare 4
  [25] ADC3TDC3 — ADC trigger 3 on timer D compare 3
  [24] ADC3TFPER — ADC trigger 3 on timer F period
  [23] ADC3TCPER — ADC trigger 3 on timer C period
  [22] ADC3TCC4 — ADC trigger 3 on timer C compare 4
  [21] ADC3TCC3 — ADC trigger 3 on timer C compare 3
  [20] ADC3TFC4 — ADC trigger 3 on timer F compare 4
  [19] ADC3TBRST
  [18] ADC3TBPER — ADC trigger 3 on timer B period
  [17] ADC3TBC4 — ADC trigger 3 on timer B compare 4
  [16] ADC3TBC3 — ADC trigger 3 on timer B compare 3
  [15] ADC3TFC3 — ADC trigger 3 on timer F compare 3
  [14] ADC3TARST
  [13] ADC3TAPER — ADC trigger 3 on timer A period
  [12] ADC3TAC4 — ADC trigger 3 on timer A compare 4
  [11] ADC3TAC3 — ADC trigger 3 on timer A compare 3
  [10] ADC3TFC2 — ADC trigger 3 on timer F compare 2
  [n+4] ADC3EEV{n} (n=1..5)
  [4] ADC3MPER — ADC trigger 3 on master period
  [n-1] ADC3MC{n} (n=1..4) — ADC trigger 3 on master compare {n}
0x748 ADC4R — HRTIM ADC trigger 4 register
  [31] ADC4TERST
  [30] ADC4TEC4 — ADC trigger 4 on timer E compare 4
  [29] ADC4TEC3 — ADC trigger 4 on timer E compare 3
  [28] ADC4TEC2 — ADC trigger 4 on timer E compare 2
  [27] ADC4TDRST
  [26] ADC4TDPER — ADC trigger 4 on timer D period
  [25] ADC4TDC4 — ADC trigger 4 on timer D compare 4
  [24] ADC4TFPER — ADC trigger 4 on timer F period
  [23] ADC4TDC2 — ADC trigger 2 on timer D compare 2
  [22] ADC4TCRST
  [21] ADC4TCPER — ADC trigger 4 on timer C period
  [20] ADC4TCC4 — ADC trigger 4 on timer C compare 4
  [19] ADC4TFC4 — ADC trigger 4 on timer F compare 4
  [18] ADC4TCC2 — ADC trigger 4 on timer C compare 2
  [17] ADC4TBPER — ADC trigger 4 on timer B period
  [16] ADC4TBC4 — ADC trigger 4 on timer B compare 4
  [15] ADC4TFC3 — ADC trigger 4 on timer F compare 3
  [14] ADC4TBC2 — ADC trigger 4 on timer B compare 2
  [13] ADC4TAPER — ADC trigger 4 on timer A period
  [12] ADC4TAC4 — ADC trigger 4 on timer A compare 4
  [11] ADC4TFC2 — ADC trigger 4 on timer F compare 2
  [10] ADC4TAC2 — ADC trigger 4 on timer A compare 2
  [n-1] ADC4EEV{n} (n=6..10)
  [4] ADC4MPER — ADC trigger 4 on master period
  [n-1] ADC4MC{n} (n=1..4) — ADC trigger 4 on master compare {n}
0x74C DLLCR — HRTIM DLL control register
  [3:2] CALRTE — DLL Calibration rate
  [1] CALEN — DLL Calibration Enable
  [0] CAL — DLL Calibration Start
0x750 FLTINR1 — HRTIM fault input register 1
  [8n-1] FLT{n}LCK (n=1..4) — Fault {n} lock
  [8n-2:8n-5] FLT{n}F (n=1..4) — Fault {n} filter
  [8n-6] FLT{n}SRC (n=1..4) — Fault {n} source bit 0
  [8n-7] FLT{n}P (n=1..4) — Fault {n} polarity
  [8n-8] FLT{n}E (n=1..4) — Fault {n} enable
0x754 FLTINR2 — HRTIM fault input register 2
  [25:24] FLTSD — Fault sampling clock division
  [23] FLT8SRC_1 — Fault 8 source bit 1
  [22] FLT7SRC_1 — Fault 7 source bit 1
  [21] FLT6SRC_1
  [20] FLT5SRC_1
  [n+15] FLT{n}SRC (n=1..4) — Fault {n} source bit 1
  [15] FLT6LCK — Fault 6 lock
  [14:11] FLT6F — Fault 6 filter
  [10] FLT6SRC — FLT6SRC[0]: Fault 6 source bit 0
  [9] FLT6P — Fault 6 polarity
  [8] FLT6E — Fault 6 enable
  [7] FLT5LCK — Fault 5 lock
  [6:3] FLT5F — Fault 5 filter
  [2] FLT5SRC — FLT5SRC[0]: Fault 5 source bit 0
  [1] FLT5P — Fault 5 polarity
  [0] FLT5E — Fault 5 enable
0x758 BDMUPR — HRTIM burst DMA master timer update register
  [n+5] MCMP{n} (n=1..4) — MCMP{n}R register update enable
  [5] MREP — MREP register update enable
  [4] MPER — MPER register update enable
  [3] MCNT — MCNTR register update enable
  [2] MDIER — MDIER register update enable
  [1] MICR — MICR register update enable
  [0] MCR — MCR register update enable
0x75C BDTAUPR — HRTIM burst DMA timer A update register
  [26] TIMACODER, [25] TIMACOFER, [24] TIMACOTRGR, [23] TIMAEESELR, [22] TIMAEEFR3, [21] TIMACR2, [20] TIMAFLTR, [19] TIMAOUTR, [18] TIMACHPR, [17] TIMARSTR, [16] TIMAEEFR2, [15] TIMAEEFR1, [14] TIMARST2R, [13] TIMASET2R, [12] TIMARST1R, [11] TIMASET1R, [10] TIMADTR, [n+5] TIMACMP{n} (n=1..4), [5] TIMAREP, [4] TIMAPER, [3] TIMACNT, [2] TIMADIER, [1] TIMAICR, [0] TIMACR
0x760 BDTBUPR — HRTIM burst DMA timer B update register
  [26] TIMBCODER, [25] TIMBCOFER, [24] TIMBCOTRGR, [23] TIMBEESELR, [22] TIMBEEFR3, [21] TIMBCR2, [20] TIMBFLTR, [19] TIMBOUTR, [18] TIMBCHPR, [17] TIMBRSTR, [16] TIMBEEFR2, [15] TIMBEEFR1, [14] TIMBRST2R, [13] TIMBSET2R, [12] TIMBRST1R, [11] TIMBSET1R, [10] TIMBDTR, [n+5] TIMBCMP{n} (n=1..4), [5] TIMBREP, [4] TIMBPER, [3] TIMBCNT, [2] TIMBDIER, [1] TIMBICR, [0] TIMBCR
0x764 BDTCUPR — HRTIM burst DMA timer C update register
  [26] TIMCCODER, [25] TIMCCOFER, [24] TIMCCOTRGR, [23] TIMCEESELR, [22] TIMCEEFR3, [21] TIMCCR2, [20] TIMCFLTR, [19] TIMCOUTR, [18] TIMCCHPR, [17] TIMCRSTR, [16] TIMCEEFR2, [15] TIMCEEFR1, [14] TIMCRST2R, [13] TIMCSET2R, [12] TIMCRST1R, [11] TIMCSET1R, [10] TIMCDTR, [n+5] TIMCCMP{n} (n=1..4), [5] TIMCREP, [4] TIMCPER, [3] TIMCCNT, [2] TIMCDIER, [1] TIMCICR, [0] TIMCCR
0x768 BDTDUPR — HRTIM burst DMA timer D update register
  [26] TIMDCODER, [25] TIMDCOFER, [24] TIMDCOTRGR, [23] TIMDEESELR, [22] TIMDEEFR3, [21] TIMDCR2, [20] TIMDFLTR, [19] TIMDOUTR, [18] TIMDCHPR, [17] TIMDRSTR, [16] TIMDEEFR2, [15] TIMDEEFR1, [14] TIMDRST2R, [13] TIMDSET2R, [12] TIMDRST1R, [11] TIMDSET1R, [10] TIMDDTR, [n+5] TIMDCMP{n} (n=1..4), [5] TIMDREP, [4] TIMDPER, [3] TIMDCNT, [2] TIMDDIER, [1] TIMDICR, [0] TIMDCR
0x76C BDTEUPR — HRTIM burst DMA timer E update register
  [26] TIMECODER, [25] TIMECOFER, [24] TIMECOTRGR, [23] TIMEEESELR, [22] TIMEEEFR3, [21] TIMECR2, [20] TIMEFLTR, [19] TIMEOUTR, [18] TIMECHPR, [17] TIMERSTR, [16] TIMEEEFR2, [15] TIMEEEFR1, [14] TIMERST2R, [13] TIMESET2R, [12] TIMERST1R, [11] TIMESET1R, [10] TIMEDTR, [n+5] TIMECMP{n} (n=1..4), [5] TIMEREP, [4] TIMEPER, [3] TIMECNT, [2] TIMEDIER, [1] TIMEICR, [0] TIMECR
0x770 BDMADR — HRTIM burst DMA data register
  [31:0] BDMADR — Burst DMA data register
0x774 BDTFUPR — HRTIM burst DMA timer F update register
  [26] TIMFCODER, [25] TIMFCOFER, [24] TIMFCOTRGR, [23] TIMFEESELR, [22] TIMFEEFR3, [21] TIMFCR2, [20] TIMFFLTR, [19] TIMFOUTR, [18] TIMFCHPR, [17] TIMFRSTR, [16] TIMFEEFR2, [15] TIMFEEFR1, [14] TIMFRST2R, [13] TIMFSET2R, [12] TIMFRST1R, [11] TIMFSET1R, [10] TIMFDTR, [n+5] TIMFCMP{n} (n=1..4), [5] TIMFREP, [4] TIMFPER, [3] TIMFCNT, [2] TIMFDIER, [1] TIMFICR, [0] TIMFCR
0x778 ADCER — HRTIM ADC extended trigger register
  [30:26] ADC10TRG — ADC trigger 10 selection
  [25:21] ADC9TRG — ADC trigger 9 selection
  [20:16] ADC8TRG — ADC trigger 8 selection
  [14:10] ADC7TRG — ADC trigger 7 selection
  [9:5] ADC6TRG — ADC trigger 6 selection
  [4:0] ADC5TRG — ADC trigger 5 selection
0x77C ADCUR — HRTIM ADC trigger update register
  [4n-18:4n-20] AD{n}USRC (n=5..10) — ADC trigger {n} update source
0x780 ADCPS1 — HRTIM ADC post scaler register 1
  [6n-2:6n-6] ADC{n}PSC (n=1..5) — ADC {n} post scaler
0x784 ADCPS2 — HRTIM ADC post scaler register 2
  [6n-32:6n-36] ADC{n}PSC (n=6..10) — ADC {n} post scaler
0x788 FLTINR3 — HRTIM fault input register 3
  [8n-1] FLT{n}RSTM (n=1..4) — Fault {n} reset mode
  [8n-2] FLT{n}CRES (n=1..4) — Fault {n} counter reset
  [8n-3:8n-6] FLT{n}CNT (n=1..4) — Fault {n} counter
  [8n-7] FLT{n}BLKS (n=1..4) — Fault {n} blanking source
  [8n-8] FLT{n}BLKE (n=1..4) — Fault {n} blanking enable
0x78C FLTINR4 — HRTIM fault input register 4
  [8n-33] FLT{n}RSTM (n=5..8) — Fault {n} reset mode
  [8n-34] FLT{n}CRES (n=5..8) — Fault {n} counter reset
  [8n-35:8n-38] FLT{n}CNT (n=5..8) — Fault {n} counter
  [8n-39] FLT{n}BLKS (n=5..8) — Fault {n} blanking source
  [8n-40] FLT{n}BLKE (n=5..8) — Fault {n} blanking enable
0x790 FLTINR5 — HRTIM Fault input register 5
  [15] FLT8LCK — Fault 8 lock
  [14:11] FLT8F — Fault 8 filter
  [10] FLT8SRC — Fault 8 source bit 0
  [9] FLT8P — Fault 8 polarity
  [8] FLT8E — Fault 8 enable
  [7] FLT7LCK — Fault 7 lock
  [6:3] FLT7F — Fault 7 filter
  [2] FLT7SRC — Fault 7 source bit 0
  [1] FLT7P — Fault 7 polarity
  [0] FLT7E — Fault 7 enable
0x7A0 EECR4 — HRTIM Timer external event control register 4
  [17] EE13FAST — External event 3 fast mode
  [16:15] EE13SNS — External event 3 sensitivity
  [14] EE13POL — External event 3 polarity
  [13:12] EE13SRC — External event 3 source
  [11] EE12FAST — External event 2 fast mode
  [10:9] EE12SNS — External event 2 sensitivity
  [8] EE12POL — External event 2 polarity
  [7:6] EE12SRC — External event 2 source
  [5] EE11FAST — External event 11 fast mode
  [4:3] EE11SNS — External event 11 sensitivity
  [2] EE11POL — External event 11 polarity
  [1:0] EE11SRC — External event 11 source
0x7A4 EECR5 — HRTIM Timer external event control register 5
  [16:15] EE16SNS — External event 16 sensitivity
  [14] EE16POL — External event 16 polarity
  [13:12] EE16SRC — External event 16 source
  [10:9] EE15SNS — External event 15 sensitivity
  [8] EE15POL — External event 15 polarity
  [7:6] EE15SRC — External event 15 source
  [4:3] EE14SNS — External event 14 sensitivity
  [2] EE14POL — External event 14 polarity
  [1:0] EE14SRC — External event 14 source
0x7A8 EECR6 — HRTIM Timer external event control register 6
  [15:12] EE16F — External event 16 filter
  [9:6] EE15F — External event 15 filter
  [3:0] EE14F — External event 14 filter
0x7AC EECR7 — HRTIM Timer external event control register 7
  [2n-2] EE{n}SRC (n=1..16) — External event {n} source - bit 2
0x7C0 CR3 — HRTIM control register 3
  [6] RTFUDISA, [5] RTEUDISA, [4] RTDUDISA, [3] RTCUDISA, [2] RTBUDISA, [1] RTAUDISA, [0] RMUDISA
0x7FC OR — HRTIM option register
  [2] INSYNCSEL — Synchronization Input Selection
  [1] UPDENSEL — Update Enable Selection
  [0] BMTRGSEL — Update Enable Selection
